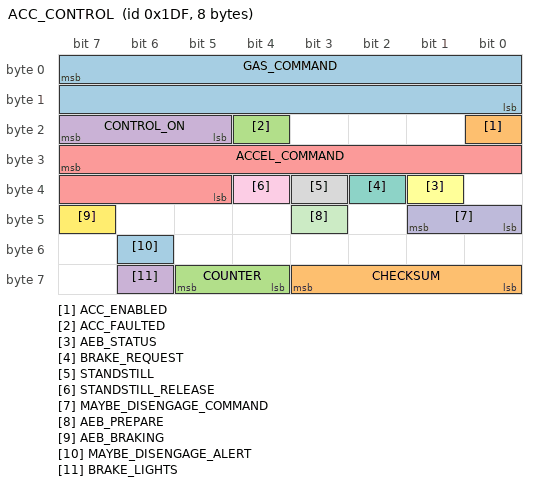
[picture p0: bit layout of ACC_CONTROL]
BO_ 479 ACC_CONTROL: 8 EON
 SG_ GAS_COMMAND : 7|16@0- (0.1,0) [0|0] "nM" XXX
 SG_ ACC_ENABLED : 16|1@0+ (1,0) [0|1] "" XXX
 SG_ ACC_FAULTED : 20|1@0+ (1,0) [0|1] "" XXX
 SG_ CONTROL_ON : 23|3@0+ (1,0) [0|5] "" XXX
 SG_ ACCEL_COMMAND : 31|11@0- (0.01,0) [0|0] "m/s2" XXX
 SG_ AEB_STATUS : 33|1@0+ (1,0) [0|1] "" XXX
 SG_ BRAKE_REQUEST : 34|1@0+ (1,0) [0|1] "" XXX
 SG_ STANDSTILL : 35|1@0+ (1,0) [0|1] "" XXX
 SG_ STANDSTILL_RELEASE : 36|1@0+ (1,0) [0|1] "" XXX
 SG_ MAYBE_DISENGAGE_COMMAND : 41|2@0+ (1,0) [0|3] "" XXX
 SG_ AEB_PREPARE : 43|1@0+ (1,0) [0|1] "" XXX
 SG_ AEB_BRAKING : 47|1@0+ (1,0) [0|1] "" XXX
 SG_ MAYBE_DISENGAGE_ALERT : 54|1@0+ (1,0) [0|1] "" XXX
 SG_ CHECKSUM : 59|4@0+ (1,0) [0|15] "" XXX
 SG_ COUNTER : 61|2@0+ (1,0) [0|3] "" XXX
 SG_ BRAKE_LIGHTS : 62|1@0+ (1,0) [0|1] "" XXX

BO_ 495 ACC_CONTROL_ON: 8 XXX
 SG_ SET_TO_75 : 31|8@0+ (1,0) [0|255] "" XXX
 SG_ SET_TO_30 : 39|8@0+ (1,0) [0|255] "" XXX
 SG_ ZEROS_BOH : 23|8@0+ (1,0) [0|255] "" XXX
 SG_ ZEROS_BOH2 : 47|16@0+ (1,0) [0|255] "" XXX
 SG_ SET_TO_FF : 15|8@0+ (1,0) [0|255] "" XXX
 SG_ COAST_BRAKE : 17|1@0+ (1,0) [0|0] "" XXX
 SG_ SET_TO_3 : 6|7@0+ (1,0) [0|4095] "" XXX
 SG_ CONTROL_ON : 7|1@0+ (1,0) [0|1] "" XXX
 SG_ CHECKSUM : 59|4@0+ (1,0) [0|15] "" XXX
 SG_ COUNTER : 61|2@0+ (1,0) [0|3] "" XXX

CM_ SG_ 479 CONTROL_ON "Set to 5 when car is being controlled";
CM_ SG_ 479 AEB_STATUS "set for the duration of AEB event";
CM_ SG_ 479 AEB_BRAKING "set when braking is commanded during AEB event";
CM_ SG_ 479 AEB_PREPARE "set 1s before AEB";
CM_ SG_ 479 MAYBE_DISENGAGE_COMMAND "Might signal the powertrain to disengage or prevent engagement on radar-side ACC faults";
CM_ SG_ 479 MAYBE_DISENGAGE_ALERT "Signals the instrument cluster to display an ACC fault";
